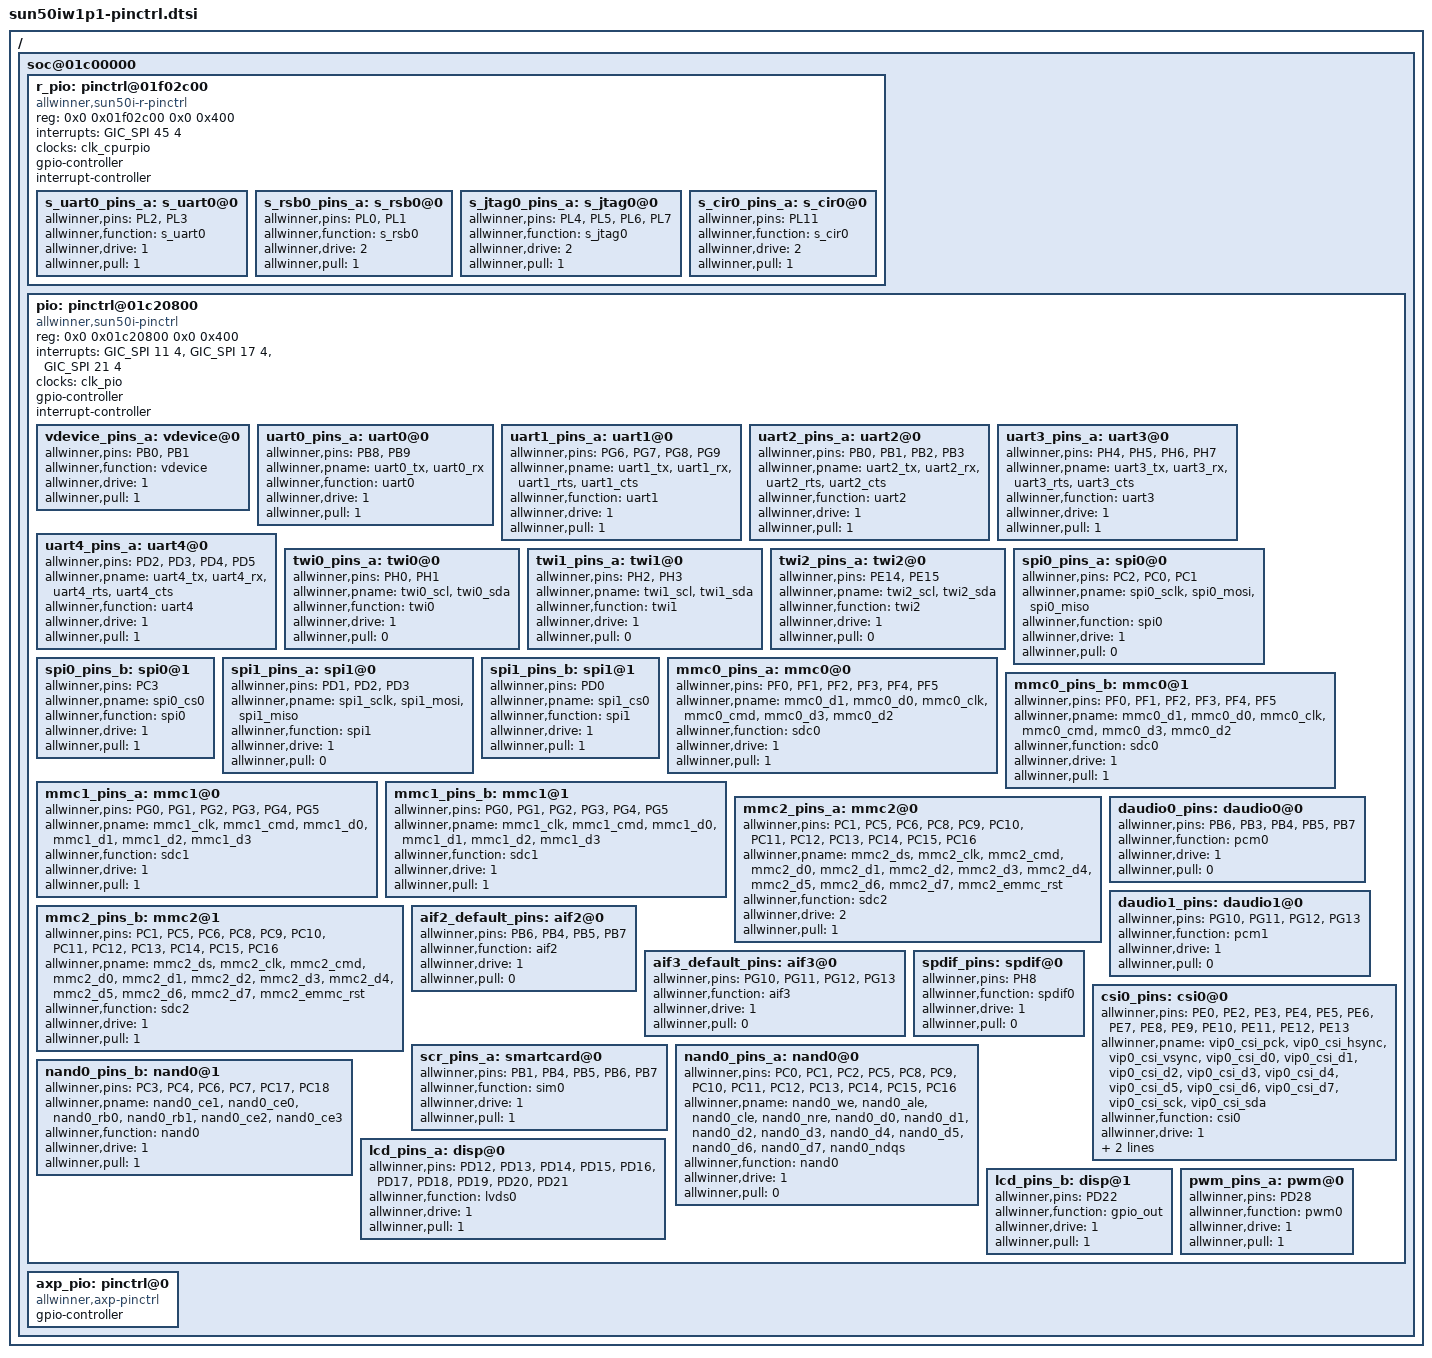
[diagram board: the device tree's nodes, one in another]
/*
 * Allwinner 1689 pin config info.
 */

/ {
	soc@01c00000{
		r_pio: pinctrl@01f02c00 {
			compatible = "allwinner,sun50i-r-pinctrl";
			reg = <0x0 0x01f02c00 0x0 0x400>;
			interrupts = <GIC_SPI 45 4>;
			clocks = <&clk_cpurpio>;
			//resets = <&apb0_rst 0>;
			gpio-controller;
			interrupt-controller;
			#interrupt-cells = <2>;
			#size-cells = <0>;
			#gpio-cells = <6>;

			s_uart0_pins_a: s_uart0@0 {
				allwinner,pins = "PL2", "PL3";
				allwinner,function = "s_uart0";
				allwinner,drive = <1>;
				allwinner,pull = <1>;
			};

			s_rsb0_pins_a: s_rsb0@0 {
				allwinner,pins = "PL0", "PL1";
				allwinner,function = "s_rsb0";
				allwinner,drive = <2>;
				allwinner,pull = <1>;
			};

			s_jtag0_pins_a: s_jtag0@0 {
				allwinner,pins = "PL4", "PL5", "PL6", "PL7";
				allwinner,function = "s_jtag0";
				allwinner,drive = <2>;
				allwinner,pull = <1>;
			};

			s_cir0_pins_a: s_cir0@0 {
				allwinner,pins = "PL11";
				allwinner,function = "s_cir0";
				allwinner,drive = <2>;
				allwinner,pull = <1>;
			};
		};

		pio: pinctrl@01c20800 {
			compatible = "allwinner,sun50i-pinctrl";
			reg = <0x0 0x01c20800 0x0 0x400>;
			interrupts = <GIC_SPI 11 4>,
				     <GIC_SPI 17 4>,
				     <GIC_SPI 21 4>;
			clocks = <&clk_pio>;
			gpio-controller;
			interrupt-controller;
			#interrupt-cells = <2>;
			#size-cells = <0>;
			#gpio-cells = <6>;

			vdevice_pins_a: vdevice@0 {
				allwinner,pins = "PB0", "PB1";
				allwinner,function = "vdevice";
				allwinner,drive = <1>;
				allwinner,pull = <1>;
			};

			uart0_pins_a: uart0@0 {
				allwinner,pins = "PB8", "PB9";
				allwinner,pname = "uart0_tx", "uart0_rx";
				allwinner,function = "uart0";
				allwinner,drive = <1>;
				allwinner,pull = <1>;
			};

			uart1_pins_a: uart1@0 {
				allwinner,pins = "PG6", "PG7", "PG8", "PG9";
				allwinner,pname = "uart1_tx", "uart1_rx", "uart1_rts", "uart1_cts";
				allwinner,function = "uart1";
				allwinner,drive = <1>;
				allwinner,pull = <1>;
			};

			uart2_pins_a: uart2@0 {
				allwinner,pins = "PB0", "PB1", "PB2", "PB3";
				allwinner,pname = "uart2_tx", "uart2_rx", "uart2_rts", "uart2_cts";
				allwinner,function = "uart2";
				allwinner,drive = <1>;
				allwinner,pull = <1>;
			};

			uart3_pins_a: uart3@0 {
				allwinner,pins = "PH4", "PH5", "PH6", "PH7";
				allwinner,pname = "uart3_tx", "uart3_rx", "uart3_rts", "uart3_cts";
				allwinner,function = "uart3";
				allwinner,drive = <1>;
				allwinner,pull = <1>;
			};

			uart4_pins_a: uart4@0 {
				allwinner,pins = "PD2", "PD3", "PD4", "PD5";
				allwinner,pname = "uart4_tx", "uart4_rx", "uart4_rts", "uart4_cts";
				allwinner,function = "uart4";
				allwinner,drive = <1>;
				allwinner,pull = <1>;
			};

			twi0_pins_a: twi0@0 {
				allwinner,pins = "PH0", "PH1";
				allwinner,pname = "twi0_scl", "twi0_sda";
				allwinner,function = "twi0";
				allwinner,drive = <1>;
				allwinner,pull = <0>;
			};

			twi1_pins_a: twi1@0 {
				allwinner,pins = "PH2", "PH3";
				allwinner,pname = "twi1_scl", "twi1_sda";
				allwinner,function = "twi1";
				allwinner,drive = <1>;
				allwinner,pull = <0>;
			};

			twi2_pins_a: twi2@0 {
				allwinner,pins = "PE14", "PE15";
				allwinner,pname = "twi2_scl", "twi2_sda";
				allwinner,function = "twi2";
				allwinner,drive = <1>;
				allwinner,pull = <0>;
			};

			spi0_pins_a: spi0@0 {
				allwinner,pins = "PC2", "PC0", "PC1";
				allwinner,pname = "spi0_sclk", "spi0_mosi", "spi0_miso";
				allwinner,function = "spi0";
				allwinner,drive = <1>;
				allwinner,pull = <0>;
			};

			spi0_pins_b: spi0@1 {
				allwinner,pins = "PC3";
				allwinner,pname = "spi0_cs0";
				allwinner,function = "spi0";
				allwinner,drive = <1>;
				allwinner,pull = <1>; 	// only CS should be pulled up
			};

			spi1_pins_a: spi1@0 {
				allwinner,pins = "PD1", "PD2", "PD3";
				allwinner,pname = "spi1_sclk", "spi1_mosi", "spi1_miso";
				allwinner,function = "spi1";
				allwinner,drive = <1>;
				allwinner,pull = <0>;
			};

			spi1_pins_b: spi1@1 {
				allwinner,pins = "PD0";
				allwinner,pname = "spi1_cs0";
				allwinner,function = "spi1";
				allwinner,drive = <1>;
				allwinner,pull = <1>; 	// only CS should be pulled up
			};

			mmc0_pins_a: mmc0@0 {
				allwinner,pins = "PF0", "PF1", "PF2", "PF3","PF4","PF5";
				allwinner,pname = "mmc0_d1","mmc0_d0","mmc0_clk","mmc0_cmd","mmc0_d3","mmc0_d2";
				allwinner,function = "sdc0";
				allwinner,drive = <1>;
				allwinner,pull = <1>;
			};

			mmc0_pins_b: mmc0@1 {
				allwinner,pins = "PF0", "PF1", "PF2", "PF3","PF4","PF5";
				allwinner,pname = "mmc0_d1","mmc0_d0","mmc0_clk","mmc0_cmd","mmc0_d3","mmc0_d2";
				/*allwinner,function = "io_disabled";*/
        allwinner,function = "sdc0";
				allwinner,drive = <1>;
				allwinner,pull = <1>;
			};

			mmc1_pins_a: mmc1@0 {
				allwinner,pins = "PG0", "PG1", "PG2", "PG3","PG4","PG5";
				allwinner,pname = "mmc1_clk","mmc1_cmd","mmc1_d0","mmc1_d1","mmc1_d2","mmc1_d3";
				allwinner,function = "sdc1";
				allwinner,drive = <1>;
				allwinner,pull = <1>;
			};

			mmc1_pins_b: mmc1@1 {
				allwinner,pins = "PG0", "PG1", "PG2", "PG3","PG4","PG5";
				allwinner,pname = "mmc1_clk","mmc1_cmd","mmc1_d0","mmc1_d1","mmc1_d2","mmc1_d3";
				/*allwinner,function = "io_disabled";*/
        allwinner,function = "sdc1";
				allwinner,drive = <1>;
				allwinner,pull = <1>;
			};

			mmc2_pins_a: mmc2@0 {
				allwinner,pins = "PC1","PC5", "PC6", "PC8", "PC9","PC10","PC11","PC12","PC13","PC14","PC15","PC16";
				allwinner,pname = "mmc2_ds","mmc2_clk", "mmc2_cmd", "mmc2_d0", "mmc2_d1","mmc2_d2","mmc2_d3","mmc2_d4","mmc2_d5","mmc2_d6","mmc2_d7","mmc2_emmc_rst";
				allwinner,function = "sdc2";
				allwinner,drive = <2>;
				allwinner,pull = <1>;
			};

			mmc2_pins_b: mmc2@1 {
			allwinner,pins = "PC1","PC5", "PC6", "PC8", "PC9","PC10","PC11","PC12","PC13","PC14","PC15","PC16";
			allwinner,pname = "mmc2_ds","mmc2_clk", "mmc2_cmd", "mmc2_d0", "mmc2_d1","mmc2_d2","mmc2_d3","mmc2_d4","mmc2_d5","mmc2_d6","mmc2_d7","mmc2_emmc_rst";
				allwinner,function = "sdc2";
				allwinner,drive = <1>;
				allwinner,pull = <1>;
			};

			daudio0_pins: daudio0@0 {
				allwinner,pins = "PB6", "PB3", "PB4", "PB5", "PB7";
				allwinner,function = "pcm0";
				allwinner,drive = <1>;
				allwinner,pull = <0>;
			};
			daudio1_pins: daudio1@0 {
				allwinner,pins = "PG10", "PG11", "PG12", "PG13";
				allwinner,function = "pcm1";
				allwinner,drive = <1>;
				allwinner,pull = <0>;
			};
			aif2_default_pins: aif2@0 {
				allwinner,pins = "PB6", "PB4", "PB5", "PB7";
				allwinner,function = "aif2";
				allwinner,drive = <1>;
				allwinner,pull = <0>;
			};
			aif3_default_pins: aif3@0 {
				allwinner,pins = "PG10", "PG11", "PG12", "PG13";
				allwinner,function = "aif3";
				allwinner,drive = <1>;
				allwinner,pull = <0>;
			};
			spdif_pins: spdif@0 {
				allwinner,pins = "PH8";/*ph8-spec*/
				allwinner,function = "spdif0";
				allwinner,drive = <1>;
				allwinner,pull = <0>;
			};

			csi0_pins: csi0@0 {
				allwinner,pins = "PE0","PE2","PE3","PE4","PE5","PE6","PE7","PE8","PE9","PE10","PE11","PE12","PE13";
				allwinner,pname = "vip0_csi_pck","vip0_csi_hsync","vip0_csi_vsync","vip0_csi_d0","vip0_csi_d1","vip0_csi_d2",
								"vip0_csi_d3","vip0_csi_d4","vip0_csi_d5","vip0_csi_d6","vip0_csi_d7","vip0_csi_sck","vip0_csi_sda";
				allwinner,function = "csi0";
				allwinner,drive = <1>;
				allwinner,pull = <0>;
				allwinner,data = <0>;
			};

			scr_pins_a: smartcard@0 {
				allwinner,pins = "PB1", "PB4", "PB5", "PB6","PB7";
				allwinner,function = "sim0";
				allwinner,drive = <1>;
				allwinner,pull = <1>;
			};

			nand0_pins_a: nand0@0 {
				allwinner,pins ="PC0", "PC1", "PC2", "PC5", "PC8", "PC9", "PC10", "PC11", "PC12", "PC13","PC14", "PC15","PC16";
				allwinner,pname= "nand0_we", "nand0_ale", "nand0_cle", "nand0_nre", "nand0_d0", "nand0_d1", "nand0_d2", "nand0_d3", "nand0_d4", "nand0_d5", "nand0_d6", "nand0_d7", "nand0_ndqs";
				allwinner,function = "nand0";
				allwinner,drive = <1>;
				allwinner,pull = <0>;
			};

			nand0_pins_b: nand0@1 {
				allwinner,pins ="PC3", "PC4", "PC6", "PC7", "PC17","PC18";
				allwinner,pname= "nand0_ce1", "nand0_ce0", "nand0_rb0", "nand0_rb1", "nand0_ce2", "nand0_ce3";
				allwinner,function = "nand0";
				allwinner,drive = <1>;
				allwinner,pull = <1>;// only RB&CE should be pulled up
			};

			lcd_pins_a: disp@0 {
				allwinner,pins = "PD12", "PD13", "PD14", "PD15", "PD16", "PD17", "PD18", "PD19", "PD20", "PD21";
				allwinner,function = "lvds0";
				allwinner,drive = <1>;
				allwinner,pull = <1>;
			};

			lcd_pins_b: disp@1 {
				allwinner,pins = "PD22";
				allwinner,function = "gpio_out";
				allwinner,drive = <1>;
				allwinner,pull = <1>;
			};

			pwm_pins_a: pwm@0 {
				allwinner,pins = "PD28";
				allwinner,function = "pwm0";
				allwinner,drive = <1>;
				allwinner,pull = <1>;
			};
		};

		axp_pio: pinctrl@0 {
			compatible = "allwinner,axp-pinctrl";
			gpio-controller;
			#size-cells = <0>;
			#gpio-cells = <6>;
		};
	};
};
